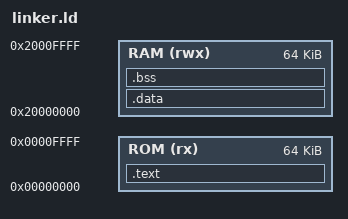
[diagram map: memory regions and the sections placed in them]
MEMORY
{
    ROM (rx)  : ORIGIN = 0x00000000, LENGTH = 64K
    RAM (rwx) : ORIGIN = 0x20000000, LENGTH = 64K
}

SECTIONS
{
    .text : {
        *(.text*)
    } > ROM
    
    .data : {
        *(.data*)
    } > RAM
    
    .bss : {
        *(.bss*)
    } > RAM
} 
